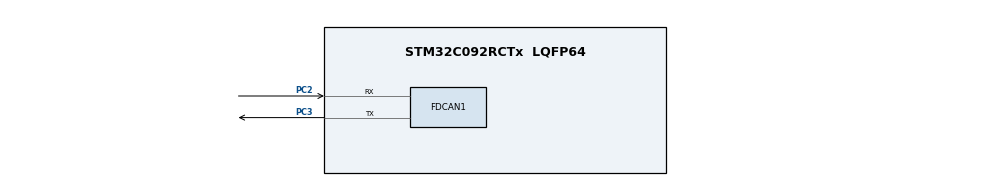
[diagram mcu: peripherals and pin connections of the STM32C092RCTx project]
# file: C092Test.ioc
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FDCAN1.AutoRetransmission=ENABLE
FDCAN1.CalculateBaudRateNominal=500000
FDCAN1.CalculateTimeBitNominal=2000
FDCAN1.CalculateTimeQuantumNominal=125.0
FDCAN1.NominalPrescaler=6
FDCAN1.NominalTimeSeg1=13
FDCAN1.NominalTimeSeg2=2
FDCAN1.TransmitPause=ENABLE
Mcu.Family=STM32C0
Mcu.Name=STM32C092RCTx
Mcu.Package=LQFP64
NUCLEO-C092RC.BUTTON=1
NUCLEO-C092RC.Bsp_Common_DEMO=true
NUCLEO-C092RC.LD1=true
NUCLEO-C092RC.LD2=true
NUCLEO-C092RC.VCP=true
NVIC.EXTI4_15_IRQn=true\:0\:0\:false\:false\:true\:false\:true\:true
NVIC.FDCAN1_IT0_IRQn=true\:0\:0\:false\:false\:true\:true\:true\:true
NVIC.FDCAN1_IT1_IRQn=true\:0\:0\:false\:false\:true\:true\:true\:true
NVIC.TIM14_IRQn=true\:0\:0\:false\:false\:true\:true\:true\:true
PA13.GPIO_Label=SWDIO
PA13.Signal=DEBUG_SWDIO
PA14-BOOT0.GPIO_Label=SWCLK
PA14-BOOT0.Signal=DEBUG_SWCLK
PA2.Signal=USART2_TX
PA3.Signal=USART2_RX
PC14-OSCX_IN(PC14).GPIO_Label=OSCX_IN
PC14-OSCX_IN(PC14).Mode=LSE-External-Oscillator
PC14-OSCX_IN(PC14).Signal=RCC_OSCX_IN
PC15-OSCX_OUT(PC15).GPIO_Label=OSCX_OUT
PC15-OSCX_OUT(PC15).Mode=LSE-External-Oscillator
PC15-OSCX_OUT(PC15).Signal=RCC_OSCX_OUT
PC2.Mode=FDCAN_Activate
PC2.Signal=FDCAN1_RX
PC3.Mode=FDCAN_Activate
PC3.Signal=FDCAN1_TX
PF0-OSC_IN(PF0).GPIO_Label=OSC_IN
PF0-OSC_IN(PF0).Mode=HSE-External-Oscillator
PF0-OSC_IN(PF0).Signal=RCC_OSC_IN
PF1-OSC_OUT(PF1).GPIO_Label=OSC_OUT
PF1-OSC_OUT(PF1).Mode=HSE-External-Oscillator
PF1-OSC_OUT(PF1).Signal=RCC_OSC_OUT
ProjectManager.HeapSize=0x200
ProjectManager.StackSize=0x400
ProjectManager.TargetToolchain=CMake
RCC.ADCFreq_Value=48000000
RCC.AHBFreq_Value=48000000
RCC.CortexFreq_Value=48000000
RCC.EXTERNAL_CLOCK_VALUE=12288000
RCC.EnableCSSLSE=true
RCC.EnbaleCSS=true
RCC.HCLKFreq_Value=48000000
RCC.HSE_VALUE=48000000
RCC.HSI_VALUE=48000000
RCC.RTCClockSelection=RCC_RTCCLKSOURCE_LSE
RCC.SYSCLKFreq_VALUE=48000000
RCC.SYSCLKSource=RCC_SYSCLKSOURCE_HSE
TIM14.Period=999
TIM14.Prescaler=47
VP_NUCLEO-C092RC_VS_BSP_COMMON.Mode=COMMON
VP_RTC_VS_RTC_Activate.Mode=RTC_Enabled
VP_TIM14_VS_ClockSourceINT.Mode=Enable_Timer
board=NUCLEO-C092RC

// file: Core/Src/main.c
/* USER CODE BEGIN Header */
/**
  ******************************************************************************
  * @file           : main.c
  * @brief          : Main program body
  ******************************************************************************
  * @attention
  *
  * Copyright (c) 2026 STMicroelectronics.
  * All rights reserved.
  *
  * This software is licensed under terms that can be found in the LICENSE file
  * in the root directory of this software component.
  * If no LICENSE file comes with this software, it is provided AS-IS.
  *
  ******************************************************************************
  */
/* USER CODE END Header */
#include "main.h"

/* USER CODE BEGIN Includes */
#include "CO_app_STM32.h"
/* USER CODE END Includes */

COM_InitTypeDef BspCOMInit;
__IO uint32_t BspButtonState = BUTTON_RELEASED;

FDCAN_HandleTypeDef hfdcan1;

RTC_HandleTypeDef hrtc;

TIM_HandleTypeDef htim14;

void SystemClock_Config(void);
static void MX_GPIO_Init(void);
static void MX_FDCAN1_Init(void);
static void MX_TIM14_Init(void);
static void MX_RTC_Init(void);

int main(void)
{

  /* MCU Configuration--------------------------------------------------------*/

  /* Reset of all peripherals, Initializes the Flash interface and the Systick. */
  HAL_Init();

  /* Configure the system clock */
  SystemClock_Config();

  /* Initialize all configured peripherals */
  MX_GPIO_Init();
  MX_FDCAN1_Init();
  MX_TIM14_Init();
  MX_RTC_Init();
  /* USER CODE BEGIN 2 */

  /* BEGIN INITIALIZE CANopenNodeSTM32 */
  CANopenNodeSTM32 canOpenNodeSTM32;
  canOpenNodeSTM32.CANHandle = &hfdcan1;
  canOpenNodeSTM32.HWInitFunction = MX_FDCAN1_Init;
  canOpenNodeSTM32.timerHandle = &htim14;
  canOpenNodeSTM32.desiredNodeID = 1;
  canOpenNodeSTM32.baudrate = 500;
  canopen_app_init(&canOpenNodeSTM32);
  /* END INITIALIZE CANopenNodeSTM32 */

  /* USER CODE END 2 */

  /* Initialize leds */
  BSP_LED_Init(LED_GREEN);
  BSP_LED_Init(LED_BLUE);

  /* Initialize USER push-button, will be used to trigger an interrupt each time it's pressed.*/
  BSP_PB_Init(BUTTON_USER, BUTTON_MODE_EXTI);

  /* Initialize COM1 port (115200, 8 bits (7-bit data + 1 stop bit), no parity */
  BspCOMInit.BaudRate   = 115200;
  BspCOMInit.WordLength = COM_WORDLENGTH_8B;
  BspCOMInit.StopBits   = COM_STOPBITS_1;
  BspCOMInit.Parity     = COM_PARITY_NONE;
  BspCOMInit.HwFlowCtl  = COM_HWCONTROL_NONE;
  if (BSP_COM_Init(COM1, &BspCOMInit) != BSP_ERROR_NONE)
  {
    Error_Handler();
  }

  /* USER CODE BEGIN BSP */

  /* -- Sample board code to send message over COM1 port ---- */
  printf("Welcome to STM32 world !\n\r");

  /* -- Sample board code to switch on leds ---- */
  BSP_LED_On(LED_GREEN);
  BSP_LED_On(LED_BLUE);

  /* USER CODE END BSP */

  /* Infinite loop */
  /* USER CODE BEGIN WHILE */
  while (1)
  {

    /* -- Sample board code for User push-button in interrupt mode ---- */
    if (BspButtonState == BUTTON_PRESSED)
    {
      /* Update button state */
      BspButtonState = BUTTON_RELEASED;
      /* -- Sample board code to toggle leds ---- */
      BSP_LED_Toggle(LED_GREEN);
      BSP_LED_Toggle(LED_BLUE);

      /* ..... Perform your action ..... */
    }
    /* USER CODE END WHILE */

    canopen_app_process();

  }
}

void SystemClock_Config(void)
{
  RCC_OscInitTypeDef RCC_OscInitStruct = {0};
  RCC_ClkInitTypeDef RCC_ClkInitStruct = {0};

  __HAL_FLASH_SET_LATENCY(FLASH_LATENCY_1);

  /** Configure LSE Drive Capability
  */
  __HAL_RCC_LSEDRIVE_CONFIG(RCC_LSEDRIVE_LOW);

  /** Initializes the RCC Oscillators according to the specified parameters
  * in the RCC_OscInitTypeDef structure.
  */
  RCC_OscInitStruct.OscillatorType = RCC_OSCILLATORTYPE_HSE|RCC_OSCILLATORTYPE_LSE;
  RCC_OscInitStruct.HSEState = RCC_HSE_ON;
  RCC_OscInitStruct.LSEState = RCC_LSE_ON;
  if (HAL_RCC_OscConfig(&RCC_OscInitStruct) != HAL_OK)
  {
    Error_Handler();
  }

  /** Initializes the CPU, AHB and APB buses clocks
  */
  RCC_ClkInitStruct.ClockType = RCC_CLOCKTYPE_HCLK|RCC_CLOCKTYPE_SYSCLK
                              |RCC_CLOCKTYPE_PCLK1;
  RCC_ClkInitStruct.SYSCLKSource = RCC_SYSCLKSOURCE_HSE;
  RCC_ClkInitStruct.SYSCLKDivider = RCC_SYSCLK_DIV1;
  RCC_ClkInitStruct.AHBCLKDivider = RCC_HCLK_DIV1;
  RCC_ClkInitStruct.APB1CLKDivider = RCC_APB1_DIV1;

  if (HAL_RCC_ClockConfig(&RCC_ClkInitStruct, FLASH_LATENCY_1) != HAL_OK)
  {
    Error_Handler();
  }

  /** Enables the Clock Security System
  */
  HAL_RCC_EnableCSS();

  /** Enables the Clock Security System
  */
  HAL_RCC_EnableLSECSS();
}

static void MX_FDCAN1_Init(void)
{

  hfdcan1.Instance = FDCAN1;
  hfdcan1.Init.ClockDivider = FDCAN_CLOCK_DIV1;
  hfdcan1.Init.FrameFormat = FDCAN_FRAME_CLASSIC;
  hfdcan1.Init.Mode = FDCAN_MODE_NORMAL;
  hfdcan1.Init.AutoRetransmission = ENABLE;
  hfdcan1.Init.TransmitPause = ENABLE;
  hfdcan1.Init.ProtocolException = DISABLE;
  hfdcan1.Init.NominalPrescaler = 6;
  hfdcan1.Init.NominalSyncJumpWidth = 1;
  hfdcan1.Init.NominalTimeSeg1 = 13;
  hfdcan1.Init.NominalTimeSeg2 = 2;
  hfdcan1.Init.DataPrescaler = 1;
  hfdcan1.Init.DataSyncJumpWidth = 1;
  hfdcan1.Init.DataTimeSeg1 = 1;
  hfdcan1.Init.DataTimeSeg2 = 1;
  hfdcan1.Init.StdFiltersNbr = 0;
  hfdcan1.Init.ExtFiltersNbr = 0;
  hfdcan1.Init.TxFifoQueueMode = FDCAN_TX_FIFO_OPERATION;
  if (HAL_FDCAN_Init(&hfdcan1) != HAL_OK)
  {
    Error_Handler();
  }

}

static void MX_RTC_Init(void)
{

  /** Initialize RTC Only
  */
  hrtc.Instance = RTC;
  hrtc.Init.HourFormat = RTC_HOURFORMAT_24;
  hrtc.Init.AsynchPrediv = 127;
  hrtc.Init.SynchPrediv = 255;
  hrtc.Init.OutPut = RTC_OUTPUT_DISABLE;
  hrtc.Init.OutPutRemap = RTC_OUTPUT_REMAP_NONE;
  hrtc.Init.OutPutPolarity = RTC_OUTPUT_POLARITY_HIGH;
  hrtc.Init.OutPutType = RTC_OUTPUT_TYPE_OPENDRAIN;
  hrtc.Init.OutPutPullUp = RTC_OUTPUT_PULLUP_NONE;
  if (HAL_RTC_Init(&hrtc) != HAL_OK)
  {
    Error_Handler();
  }

}

static void MX_TIM14_Init(void)
{

  htim14.Instance = TIM14;
  htim14.Init.Prescaler = 47;
  htim14.Init.CounterMode = TIM_COUNTERMODE_UP;
  htim14.Init.Period = 999;
  htim14.Init.ClockDivision = TIM_CLOCKDIVISION_DIV1;
  htim14.Init.AutoReloadPreload = TIM_AUTORELOAD_PRELOAD_DISABLE;
  if (HAL_TIM_Base_Init(&htim14) != HAL_OK)
  {
    Error_Handler();
  }

}

static void MX_GPIO_Init(void)
{

  /* GPIO Ports Clock Enable */
  __HAL_RCC_GPIOC_CLK_ENABLE();
  __HAL_RCC_GPIOF_CLK_ENABLE();
  __HAL_RCC_GPIOA_CLK_ENABLE();

}

/**
  * @brief  BSP Push Button callback
  * @param  Button Specifies the pressed button
  * @retval None
  */
void BSP_PB_Callback(Button_TypeDef Button)
{
  if (Button == BUTTON_USER)
  {
    BspButtonState = BUTTON_PRESSED;
  }
}

void Error_Handler(void)
{
  __disable_irq();
  while (1)
  {
  }
}
